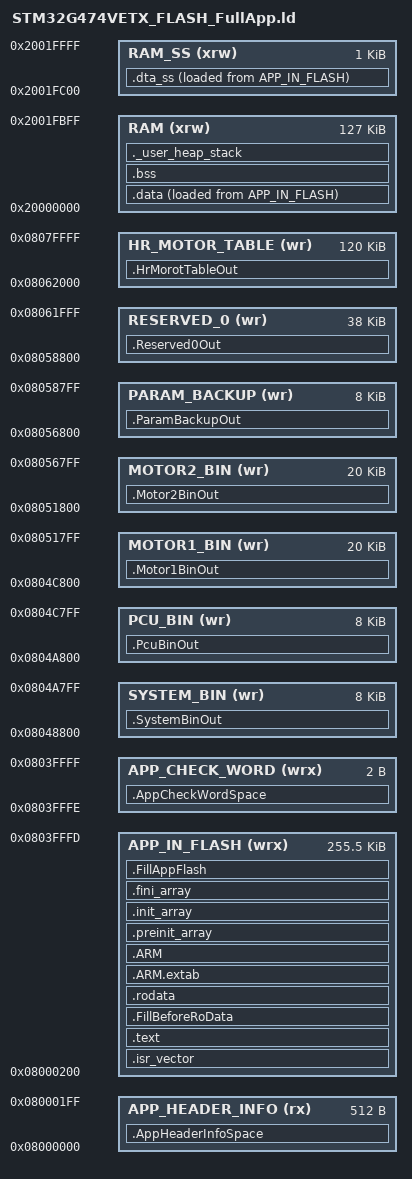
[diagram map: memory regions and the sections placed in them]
/*
******************************************************************************
**
**  File        : LinkerScript.ld
**
**  Author		: Auto-generated by STM32CubeIDE
**
**  Abstract    : Linker script for STM32G474VETx Device from STM32G4 series
**                      512Kbytes FLASH
**                      128Kbytes RAM
**
**                Set heap size, stack size and stack location according
**                to application requirements.
**
**                Set memory bank area and size if external memory is used.
**
**  Target      : STMicroelectronics STM32
**
**  Distribution: The file is distributed as is without any warranty
**                of any kind.
**
*****************************************************************************
** @attention
**
** <h2><center>&copy; COPYRIGHT(c) 2020 STMicroelectronics</center></h2>
**
** Redistribution and use in source and binary forms, with or without modification,
** are permitted provided that the following conditions are met:
**   1. Redistributions of source code must retain the above copyright notice,
**      this list of conditions and the following disclaimer.
**   2. Redistributions in binary form must reproduce the above copyright notice,
**      this list of conditions and the following disclaimer in the documentation
**      and/or other materials provided with the distribution.
**   3. Neither the name of STMicroelectronics nor the names of its contributors
**      may be used to endorse or promote products derived from this software
**      without specific prior written permission.
**
** THIS SOFTWARE IS PROVIDED BY THE COPYRIGHT HOLDERS AND CONTRIBUTORS "AS IS"
** AND ANY EXPRESS OR IMPLIED WARRANTIES, INCLUDING, BUT NOT LIMITED TO, THE
** IMPLIED WARRANTIES OF MERCHANTABILITY AND FITNESS FOR A PARTICULAR PURPOSE ARE
** DISCLAIMED. IN NO EVENT SHALL THE COPYRIGHT HOLDER OR CONTRIBUTORS BE LIABLE
** FOR ANY DIRECT, INDIRECT, INCIDENTAL, SPECIAL, EXEMPLARY, OR CONSEQUENTIAL
** DAMAGES (INCLUDING, BUT NOT LIMITED TO, PROCUREMENT OF SUBSTITUTE GOODS OR
** SERVICES; LOSS OF USE, DATA, OR PROFITS; OR BUSINESS INTERRUPTION) HOWEVER
** CAUSED AND ON ANY THEORY OF LIABILITY, WHETHER IN CONTRACT, STRICT LIABILITY,
** OR TORT (INCLUDING NEGLIGENCE OR OTHERWISE) ARISING IN ANY WAY OUT OF THE USE
** OF THIS SOFTWARE, EVEN IF ADVISED OF THE POSSIBILITY OF SUCH DAMAGE.
**
*****************************************************************************
*/

/* Entry Point */
ENTRY(Reset_Handler)

/* Highest address of the user mode stack */
_estack = ORIGIN(RAM) + LENGTH(RAM);	/* end of "RAM" Ram type memory */

_Min_Heap_Size = 0x100 ;	/* required amount of heap  */
_Min_Stack_Size = 0x400 ;	/* required amount of stack */

/* Memories definition */
MEMORY
{
    RAM (xrw)			:ORIGIN =   0x20000000  ,LENGTH =   127K
    RAM_SS (xrw)		:ORIGIN =   0x2001FC00  ,LENGTH =   1K
  	
	SYSTEM_BIN(wr)		:ORIGIN = 	0x8048800	,LENGTH = 	8K
	PCU_BIN(wr)			:ORIGIN = 	0x804A800	,LENGTH = 	8K
	MOTOR1_BIN(wr)		:ORIGIN = 	0x804C800	,LENGTH = 	20K
	MOTOR2_BIN(wr)		:ORIGIN = 	0x8051800	,LENGTH = 	20K
	PARAM_BACKUP(wr)	:ORIGIN = 	0x8056800	,LENGTH = 	8K
	RESERVED_0(wr)		:ORIGIN = 	0x8058800	,LENGTH = 	38K
	HR_MOTOR_TABLE(wr)  :ORIGIN = 	0x8062000	,LENGTH = 	120K
/*	RESERVED_1(wr)		:ORIGIN = 	0x803B000	,LENGTH = 	20K*/
	
	
	APP_HEADER_INFO(rx)	:ORIGIN =   0x8000000   ,LENGTH =   512
	APP_IN_FLASH(wrx)	:ORIGIN = 	0x8000200	,LENGTH = 	256K-LENGTH(APP_HEADER_INFO)-2
	APP_CHECK_WORD(wrx) :ORIGIN =   0x803FFFE	,LENGTH =   2
}

/* Sections */
SECTIONS
{
	.SystemBinOut :
	{
	    . = ALIGN(4);
	    *(.SystemBin);
/*
	    . = ORIGIN(SYSTEM_BIN)+LENGTH(SYSTEM_BIN)-1;	    
	    BYTE(0xFF);
*/	    
	} >SYSTEM_BIN = 0xFF
	
	.PcuBinOut :
	{
		. = ALIGN(4);
		*(.PcuBin);
/*
	    . = ORIGIN(PCU_BIN)+LENGTH(PCU_BIN)-1;
	    BYTE(0xFF);
*/ 
	} >PCU_BIN = 0xFF
	
	.Motor1BinOut :
	{
		. = ALIGN(4);
		*(.Motor1Bin);
/*		
	    . = ORIGIN(MOTOR1_BIN)+LENGTH(MOTOR1_BIN)-1;
	    BYTE(0xFF);
*/
	} >MOTOR1_BIN = 0xFF
	
	.Motor2BinOut :
	{
		. = ALIGN(4);
		*(.Motor2Bin);

	    . = ORIGIN(MOTOR2_BIN)+LENGTH(MOTOR2_BIN)-1;
	    BYTE(0xFF);

	} >MOTOR2_BIN = 0xFF
	
	
	.ParamBackupOut :
	{
		. = ALIGN(4);
		*(.ParamBackup);

	    . = ORIGIN(PARAM_BACKUP)+LENGTH(PARAM_BACKUP)-1;
	    BYTE(0xFF);

	} >PARAM_BACKUP = 0xFF

	.Reserved0Out :
	{
		. = ALIGN(4);
		*(.Reserved0);
		. = ORIGIN(RESERVED_0)+LENGTH(RESERVED_0)-1;
	    BYTE(0xFF);
	}>RESERVED_0 = 0xFF
	
		.HrMorotTableOut :                                    
	{                                                         
		. = ALIGN(4);                                         
		*(.HrMorotTable);                                     
		. = ORIGIN(HR_MOTOR_TABLE)+LENGTH(HR_MOTOR_TABLE)-1;  
	    BYTE(0xFF);                                           
	}>HR_MOTOR_TABLE = 0xFF                                   

/*	.Reserved1Out :                                    */
/*	{                                                  */
/*		. = ALIGN(4);                                  */
/*		*(.Reserved1);                                 */
/*		. = ORIGIN(RESERVED_1)+LENGTH(RESERVED_1)-1;   */
/*	    BYTE(0xFF);                                    */
/*	}>RESERVED_1 = 0xFF                                */
	
	.AppHeaderInfoSpace :
	{
		. = ALIGN(4);
		*(.AppVerSpace);
		. = ORIGIN(APP_HEADER_INFO)+LENGTH(APP_HEADER_INFO)-1;
	    BYTE(0xFF);
	}>APP_HEADER_INFO = 0xFF

  /* The startup code into "FLASH" Rom type memory */
  .isr_vector :
  {
    . = ALIGN(4);
    KEEP(*(.isr_vector)) /* Startup code */
    BYTE(0xFF);
    . = ALIGN(8);
  } >APP_IN_FLASH

  /* The program code and other data into "FLASH" Rom type memory */
  .text :
  {
    . = ALIGN(8);
    _stext = .;        /* define a global symbols at start of code */
    *(.text)           /* .text sections (code) */
    *(.text*)          /* .text* sections (code) */
    *(.glue_7)         /* glue arm to thumb code */
    *(.glue_7t)        /* glue thumb to arm code */
    *(.eh_frame)

    KEEP (*(.init))
    KEEP (*(.fini))

    . = ALIGN(4);
    _etext = .;        /* define a global symbols at end of code */
  } >APP_IN_FLASH

  .FillBeforeRoData :
  {
   . = ALIGN(4);
    _sFillBeforeRoData = .;        /* define a global symbols at start of FillBeforeRoData */
    ASSERT((_etext == _sFillBeforeRoData), "error: void space exit between output section.");
  	BYTE(0xFF);
  	. = ALIGN(8);
    _eFillBeforeRoData = .;        /* define a global symbols at end of FillBeforeRoData */
  }	> APP_IN_FLASH = 0xFF

  /* Constant data into "FLASH" Rom type memory */
  .rodata :
  {    
    . = ALIGN(8);
    _srodata = .;        /* define a global symbols at start of rodata */
    ASSERT((_eFillBeforeRoData == _srodata), "error: void space exit between output section.");
    *(.rodata)         /* .rodata sections (constants, strings, etc.) */
    *(.rodata*)        /* .rodata* sections (constants, strings, etc.) */
    . = ALIGN(4);
    _erodata = .;        /* define a global symbols at end of rodata */
  } >APP_IN_FLASH

  .ARM.extab   : { 
    . = ALIGN(4);
    *(.ARM.extab* .gnu.linkonce.armextab.*)
    . = ALIGN(4);
  } >APP_IN_FLASH
  
  .ARM : {
    . = ALIGN(4);
    __exidx_start = .;
    *(.ARM.exidx*)
    __exidx_end = .;
    . = ALIGN(4);
  } >APP_IN_FLASH

  .preinit_array     :
  {
    . = ALIGN(4);
    PROVIDE_HIDDEN (__preinit_array_start = .);
    KEEP (*(.preinit_array*))
    PROVIDE_HIDDEN (__preinit_array_end = .);
    . = ALIGN(4);
  } >APP_IN_FLASH
  
  .init_array :
  {
    . = ALIGN(4);
    PROVIDE_HIDDEN (__init_array_start = .);
    KEEP (*(SORT(.init_array.*)))
    KEEP (*(.init_array*))
    PROVIDE_HIDDEN (__init_array_end = .);
    . = ALIGN(4);
  } >APP_IN_FLASH
  
  .fini_array :
  {
    . = ALIGN(4);
    PROVIDE_HIDDEN (__fini_array_start = .);
    KEEP (*(SORT(.fini_array.*)))
    KEEP (*(.fini_array*))
    PROVIDE_HIDDEN (__fini_array_end = .);
    . = ALIGN(4);
  } >APP_IN_FLASH

  /* Used by the startup to initialize data */
  _sidata = LOADADDR(.data);

  /* Initialized data sections into "RAM" Ram type memory */
  .data : 
  {
    . = ALIGN(4);
    _sdata = .;        /* create a global symbol at data start */
    *(.data)           /* .data sections */
    *(.data*)          /* .data* sections */
    *(.ram_function)
    *(.ram_function*)       
    . = ALIGN(4);
    _edata = .;        /* define a global symbol at data end */
    
  } >RAM AT> APP_IN_FLASH


  /* Uninitialized data section into "RAM" Ram type memory */
  . = ALIGN(4);
  .bss :
  {
    /* This is used by the startup in order to initialize the .bss section */
    _sbss = .;         /* define a global symbol at bss start */
    ASSERT((_edata == _sbss), "error: void space exit between output section.");
    __bss_start__ = _sbss;
    *(.bss)
    *(.bss*)
    *(COMMON)

    . = ALIGN(4);
    _ebss = .;         /* define a global symbol at bss end */
    __bss_end__ = _ebss;
  } >RAM

    /* Uninitialized data section into "RAM" Ram type memory */
  . = ALIGN(4);
  .dta_ss :
  {
    /* This is used by the startup in order to initialize the .bss section */
    _sdta_ss = .;         /* define a global symbol at bss start */
    __dta_ss_start__ = _sdta_ss;
    *(.word1st)
    *(.word2nd)
    *(.wordothers)
    *(.dta_ss*)

    . = ALIGN(4);
    _edta_ss = .;         /* define a global symbol at bss end */
    __dta_ss_end__ = _edta_ss;
  } >RAM_SS AT> APP_IN_FLASH

  .FillAppFlash :
  {
  	. = ALIGN(2);
    _sFillAppFlash = .;         /* define a global symbol at FillAppFlash start */
    . = ORIGIN(APP_IN_FLASH)+LENGTH(APP_IN_FLASH)-1;
    BYTE(0xFF);
	
  }	> APP_IN_FLASH = 0xFF

  .AppCheckWordSpace :
  {
	. = ALIGN(2);
	*(.AppCheckWordSpace);
  }>APP_CHECK_WORD = 0xFF

  /* User_heap_stack section, used to check that there is enough "RAM" Ram  type memory left */
  ._user_heap_stack :
  {
    . = ALIGN(8);
    PROVIDE ( end = . );
    PROVIDE ( _end = . );
    . = . + _Min_Heap_Size;
    . = . + _Min_Stack_Size;
    . = ALIGN(8);
  } >RAM

  /* Remove information from the compiler libraries */
  /DISCARD/ :
  {
    libc.a ( * )
    libm.a ( * )
    libgcc.a ( * )
  }

  .ARM.attributes 0 : { *(.ARM.attributes) }
}
